# AM13E23219 register map
Vendor: Texas Instruments; File version: 1.0
CPU: CM33 r0p1, little endian, MPU, FPU, VTOR, 4 interrupt priority bits
Registers are 32-bit, read-write, reset 0x0 unless marked. A register's access mark holds for its fields unless they carry their own. Offsets are from the block's base; [hi:lo] are bit positions; lines under a group give offsets from that group; {n}, {i} and the like mark numbered series; 'fields as' and 'values as' point back to an identical list.

## SDFM0 — SDFM module
Base 0x40491000
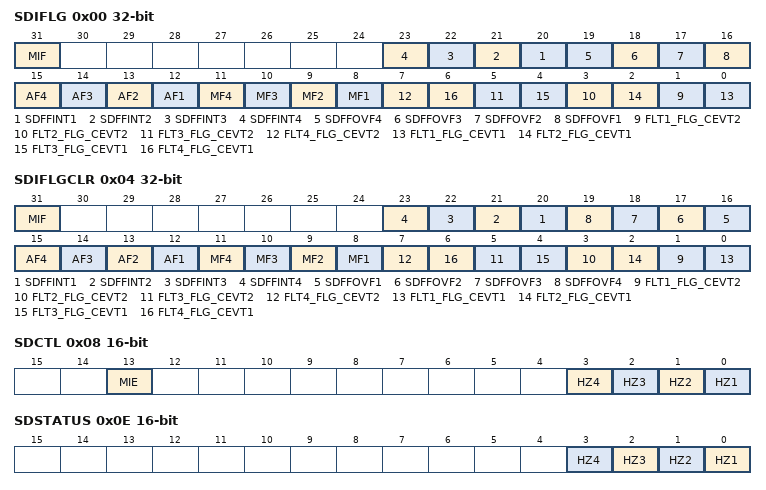
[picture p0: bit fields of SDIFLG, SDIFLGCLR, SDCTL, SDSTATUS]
0x00 SDIFLG ro — SD Interrupt Flag Register
  [31] MIF — Master Interrupt Flag
  [n+19] SDFFINT{n} (n=1..4) — SDFIFO interrupt for Ch{n}
  [19] SDFFOVF4 — FIFO Overflow Flag for Ch4
  [18] SDFFOVF3 — FIFO Overflow Flag for Ch3
  [17] SDFFOVF2 — FIFO Overflow Flag for Ch2
  [16] SDFFOVF1 — FIFO Overflow Flag for Ch1.
  [n+11] AF{n} (n=1..4) — Acknowledge flag for Filter {n}
  [n+7] MF{n} (n=1..4) — Modulator Failure for Filter {n}
  [2n-1] FLT{n}_FLG_CEVT2 (n=1..4) — Low-level Interrupt flag for Ch{n}
  [2n-2] FLT{n}_FLG_CEVT1 (n=1..4) — High-level Interrupt flag for Ch{n}
0x04 SDIFLGCLR — SD Interrupt Flag Clear Register
  [31] MIF — Master Interrupt Flag
  [n+19] SDFFINT{n} (n=1..4) — SDFIFO Interrupt flag-clear bit for Ch{n}
  [n+15] SDFFOVF{n} (n=1..4) — SDFIFO overflow clear Ch{n}
  [n+11] AF{n} (n=1..4) — Acknowledge flag for Filter {n}
  [n+7] MF{n} (n=1..4) — Modulator Failure for Filter {n}
  [2n-1] FLT{n}_FLG_CEVT2 (n=1..4) — Low-level Interrupt flag for Ch{n}
  [2n-2] FLT{n}_FLG_CEVT1 (n=1..4) — High-level Interrupt flag for Ch{n}
0x08 SDCTL 16-bit — SD Control Register
  [13] MIE — Master SDy_ERR Interrupt enable
  [n-1] HZ{n} (n=1..4) — High-level Threshold crossing (Z) flag Ch{n}
0x0C SDMFILEN 16-bit — SD Master Filter Enable
  [11] MFE — Master Filter Enable.
0x0E SDSTATUS 16-bit ro
  [n-1] HZ{n} (n=1..4) — High-level Threshold crossing (Z) flag Ch{n}
0x10 SDINTMODE 16-bit — SD Interrupt Mode register
  [0] SDINTMODESEL — CompxH/L events interrupt mode select
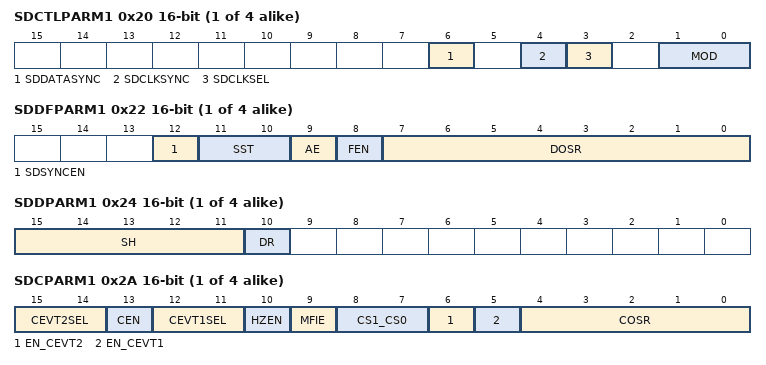
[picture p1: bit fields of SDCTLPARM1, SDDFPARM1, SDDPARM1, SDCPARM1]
{0x0+0x20*i} SDCTLPARM{i} 16-bit (i=1..4) — Control Parameter Register for Ch{i}
  [6] SDDATASYNC — Enable Synchronizer on SD data
  [4] SDCLKSYNC — Enable Synchronizer on SD clock
  [3] SDCLKSEL — SD{i} Clock source select.
  [1:0] MOD — Modulator clocking modes
{0x2+0x20*i} SDDFPARM{i} 16-bit (i=1..4) — Data Filter Parameter Register for Ch{i}
  [12] SDSYNCEN — Data Filter Reset Enable
  [11:10] SST — Data filter Structure (SincFast/1/2/3)
  [9] AE — Ack Enable
  [8] FEN — Filter Enable
  [7:0] DOSR — Data Filter Oversample Ratio= DOSR+1
{0x4+0x20*i} SDDPARM{i} 16-bit (i=1..4) — Data Parameter Register for Ch{i}
  [15:11] SH — Shift Control (# bits to shift in 16b mode)
  [10] DR — Data Representation (0/1 = 16/32b 2's complement)
{0x6+0x20*i} SDFLT{i}CMPH1 16-bit (i=1..4) — High-level Threshold Register for Ch{i}
  [14:0] HLT — High-level threshold for the comparator filter output
{0x8+0x20*i} SDFLT{i}CMPL1 16-bit (i=1..4) — Low-level Threshold Register for Ch{i}
  [14:0] LLT — Low-level threshold for the comparator filter output
{0xA+0x20*i} SDCPARM{i} 16-bit (i=1..4) — Comparator Filter Parameter Register for Ch{i}
  [15:14] CEVT2SEL — Comparator Event2 select
  [13] CEN — Comparator Enable
  [12:11] CEVT1SEL — Comparator Event1 select
  [10] HZEN — High level (Z) Threshold crossing output enable
  [9] MFIE — Modulator Failure Interrupt enable
  [8:7] CS1_CS0 — Comparator Filter Structure (SincFast/1/2/3)
  [6] EN_CEVT2 — CEVT2 Interrupt enable.
  [5] EN_CEVT1 — CEVT1 Interrupt enable.
  [4:0] COSR — Comparator Oversample Ratio. Actual rate COSR+1
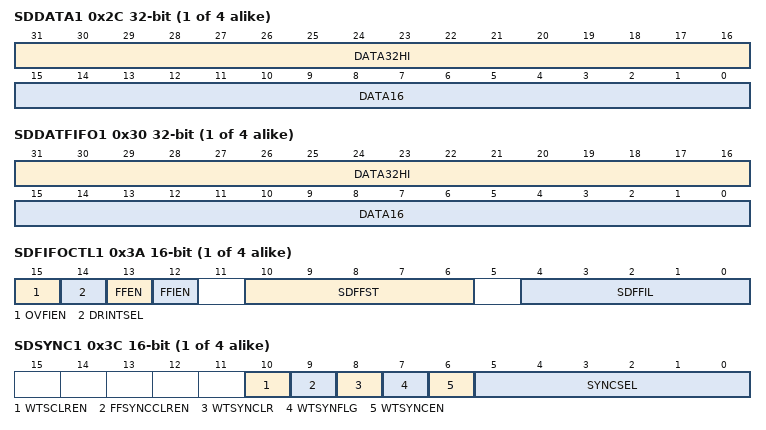
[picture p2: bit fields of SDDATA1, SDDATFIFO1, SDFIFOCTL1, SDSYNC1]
{0xC+0x20*i} SDDATA{i} ro (i=1..4) — Data Filter Data Register (16 or 32bit) for Ch{i}
  [31:16] DATA32HI — Hi-order 16b in 32b mode, 16-bit Data in 16b mode
  [15:0] DATA16 — Lo-order 16b in 32b mode
{0x10+0x20*i} SDDATFIFO{i} ro (i=1..4) — Filter Data FIFO Output(32b) for Ch{i}
  fields as SDDATA1
{0x14+0x20*i} SDCDATA{i} 16-bit access not given (i=1..4) — Comparator Filter Data Register (16b) for Ch{i}
{0x16+0x20*i} SDFLT{i}CMPH2 16-bit (i=1..4) — Second high level threhold for CH{i}
  [14:0] HLT2 — Second High level threshold.
{0x18+0x20*i} SDFLT{i}CMPHZ 16-bit (i=1..4) — High-level (Z) Threshold Register for Ch{i}
  [14:0] HLTZ — High-level threshold (Z) for the comparator filter output
{0x1A+0x20*i} SDFIFOCTL{i} 16-bit access per field (i=1..4) — FIFO Control Register for Ch{i}
  [15] OVFIEN rw — SDFIFO Overflow interrupt enable
  [14] DRINTSEL rw — Data-Ready Interrupt Source Select
  [13] FFEN rw — SDFIFO Enable
  [12] FFIEN rw — SDFIFO data ready Interrupt Enable
  [10:6] SDFFST ro — SDFIFO Status
  [4:0] SDFFIL rw — SDFIFO Interrupt Level
{0x1C+0x20*i} SDSYNC{i} 16-bit access per field (i=1..4) — SD Filter Sync control for Ch{i}
  [10] WTSCLREN rw — WTSYNFLG Clear-on-FIFOINT Enable
  [9] FFSYNCCLREN rw — FIFO Clear-on-SDSYNC Enable
  [8] WTSYNCLR rw — Wait-for-Sync Flag Clear
  [7] WTSYNFLG ro — Wait-for-Sync Flag
  [6] WTSYNCEN rw — Wait-for-Sync Enable
  [5:0] SYNCSEL rw — SDSYNC Source Select
{0x1E+0x20*i} SDFLT{i}CMPL2 16-bit (i=1..4) — Second low level threhold for CH{i}
  [14:0] LLT2 — Second low-level threshold for the comparator filter output.
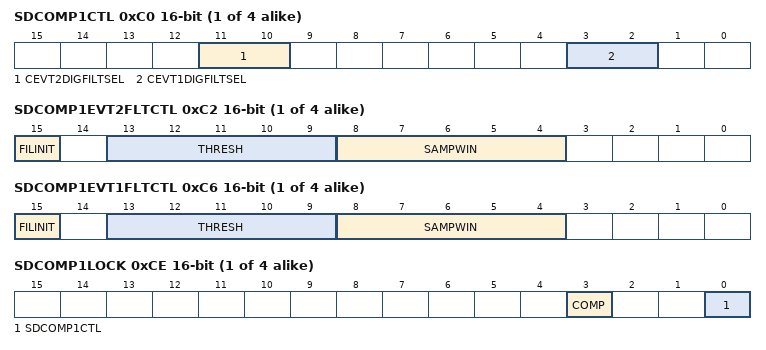
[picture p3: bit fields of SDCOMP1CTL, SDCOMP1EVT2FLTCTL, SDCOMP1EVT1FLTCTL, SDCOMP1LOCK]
{0xB0+0x10*i} SDCOMP{i}CTL 16-bit (i=1..4) — SD Comparator event filter{i} Control Register
  [11:10] CEVT2DIGFILTSEL — Low Comparator Trip Select
  [3:2] CEVT1DIGFILTSEL — High Comparator Trip Select
{0xB2+0x10*i} SDCOMP{i}EVT2FLTCTL 16-bit (i=1..4) — COMPL/CEVT2 Digital filter{i} Control Register
  [15] FILINIT — Filter Initialization Bit
  [13:9] THRESH — Majority Voting Threshold
  [8:4] SAMPWIN — Sample Window
{0xB4+0x10*i} SDCOMP{i}EVT2FLTCLKCTL 16-bit (i=1..4) — COMPL/CEVT2 Digital filter{i} Clock Control Register
  [9:0] CLKPRESCALE — Sample Clock Prescale
{0xB6+0x10*i} SDCOMP{i}EVT1FLTCTL 16-bit (i=1..4) — COMPH/CEVT1 Digital filter{i} Control Register
  fields as SDCOMP1EVT2FLTCTL
{0xB8+0x10*i} SDCOMP{i}EVT1FLTCLKCTL 16-bit (i=1..4) — COMPH/CEVT1 Digital filter{i} Clock Control Register
  [9:0] CLKPRESCALE — Sample Clock Prescale
{0xBE+0x10*i} SDCOMP{i}LOCK 16-bit (i=1..4) — SD compartor event filter{i} Lock Register
  [3] COMP — COMPevent filter registers Lock
  [0] SDCOMP{i}CTL — COMPCTL Lock
0x404 PINCM group
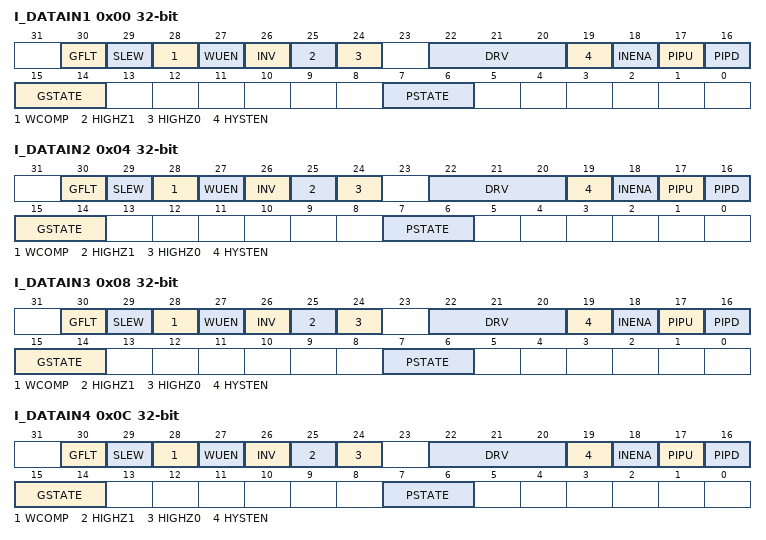
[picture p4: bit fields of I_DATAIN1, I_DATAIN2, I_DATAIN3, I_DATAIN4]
  0x00 I_DATAIN1 — Single-bit data input signal 1 for synchronous data interface
    [30] GFLT — Glitch Filter Enable
      0=DISABLE (No internal glitch filter); 1=ENABLE (Use internal glitch filter)
    [29] SLEW — Reserved Slew Rate Control
      0=DISABLE (No Slew Rate Control); 1=ENABLE (Use Slew Rate Control)
    [28] WCOMP — Wake up compare value
      0=MATCH_ZERO (Match 0 will wake); 1=MATCH_ONE (Match 1 will wake)
    [27] WUEN — Wake up enable
      0=NO_WAKEUP (Wake up not enabled); 1=WAKEUP (Wake up enabled)
    [26] INV — Invert digital input/output relative to peripheral/GPIO
      0=NO_CHNG (Input and output are non-inverted); 1=CHNG (Input and output are inverted)
    [25] HIGHZ1 — High-Z instead of high output
      0=DRV_HIGH (Pin can be driven high); 1=DRV_HIZ (Pin is tri-stated instead of driven high)
    [24] HIGHZ0 — High-Z instead of low output
      0=DRV_LOW (Pin can be driven low); 1=DRV_HIZ (Pin is tri-stated instead of driven low)
    [22:20] DRV — Drive strength options
      0=STRENGTH_0 (Lowest drive strength); {v}=STRENGTH_{v} (Drive strength {v+1}/8) (v=1..6); 7=STRENGTH_7 (Highest drive strength)
    [19] HYSTEN — Hysteresis enable
      0=DIS_HYST (No hysteresis); 1=EN_HYST (Hysteresis on)
    [18] INENA — Input enable
      0=INP_DISABLE (Inputs 0 to connected core); 1=INP_ENABLE (Inputs IO pad value to connected core)
    [17] PIPU — Pull up enable
      0=NO_PULL_UP; 1=PULL_UP
    [16] PIPD — Pull down enable
      0=NO_PULL_DOWN; 1=PULL_DOWN
    [15:14] GSTATE — GPIO Channel State
      0=UNASSIGNED (G-Channel is in Unassigned State); 1=HANDOVER (G-Channel is in Handover State); 2=CONC_NOT_LOCKED (G-Channel is in Connected State and not Locked (That is F field is allowed to change without going back through Unassigned state)); 3=CONC_LOCKED (G-Channel is in Connected State and Locked (That is F field is not allowed to change to a different non-Zero value until both G and P channels go to Unassigned))
    [7:6] PSTATE — Peripheral-Analog Channel State
      0=UNASSIGNED (P-Channel is in Unassigned State); 1=HANDOVER (P-Channel is in Handover State); 2=CONC_NOT_LOCKED (P-Channel is in Connected State and not Locked (That is F field is allowed to change without going back through Unassigned state)); 3=CONC_LOCKED (P-Channel is in Connected State and Locked (That is F field is not allowed to change to a different non-Zero value until both G and P channels go to Unassigned))
  0x04 I_DATAIN2 — Single-bit data input signal 2 for synchronous data interface
    fields as PINCM.I_DATAIN1
  0x08 I_DATAIN3 — Single-bit data input signal 3 for synchronous data interface
    fields as PINCM.I_DATAIN1
  0x0C I_DATAIN4 — Single-bit data input signal 4 for synchronous data interface
    fields as PINCM.I_DATAIN1
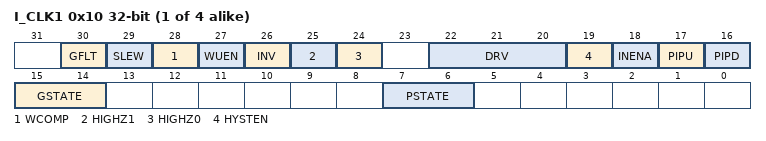
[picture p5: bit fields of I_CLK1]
  {0xC+4j} I_CLK{j} (j=1..4) — Single-bit clock signal 1 for synchronous data interface
    fields as PINCM.I_DATAIN1
0x604 FUPDATE group
  0x00 I_DATAIN1 — FUPDATE version of I_DATAIN1
    [27:2] IOADDR — IO Address. This is the address that corresponds to the SOC address[27:2] of the module IP instance specific IO signal in the "Full Write" subregion of the pinmux subregion.
    [1] LOCK — Sets lock bit
      0=NOEFFECT (Writing this value has no effect); 1=LOCK (Set channel lock bit)
    [0] GSEL — GPIO channel Select 0: Select the P-Channel for the F update 1: Select the G-Channel for the F update
      0=PCHAN (Select the P-Channel for the F update); 1=GCHAN (Select the G-Channel for the F update)
  0x04 I_DATAIN2 — FUPDATE version of I_DATAIN2
    fields as FUPDATE.I_DATAIN1
  0x08 I_DATAIN3 — FUPDATE version of I_DATAIN3
    fields as FUPDATE.I_DATAIN1
  0x0C I_DATAIN4 — FUPDATE version of I_DATAIN4
    fields as FUPDATE.I_DATAIN1
  {0xC+4j} I_CLK{j} (j=1..4) — FUPDATE version of I_CLK{j}
    fields as FUPDATE.I_DATAIN1
